# TC80_VXX register map
Vendor: Geneal MCU Ltd.; Series: ARMCM0; File version: 1.2
CPU: CM0 r0p0, little endian, no MPU, no FPU, 2 interrupt priority bits
Registers are 32-bit, read-write, reset 0x0 unless marked. A register's access mark holds for its fields unless they carry their own. Offsets are from the block's base; [hi:lo] are bit positions; {n}, {i} and the like mark numbered series.

## EXTI — External interrupt/event controller
Base 0x4900B000
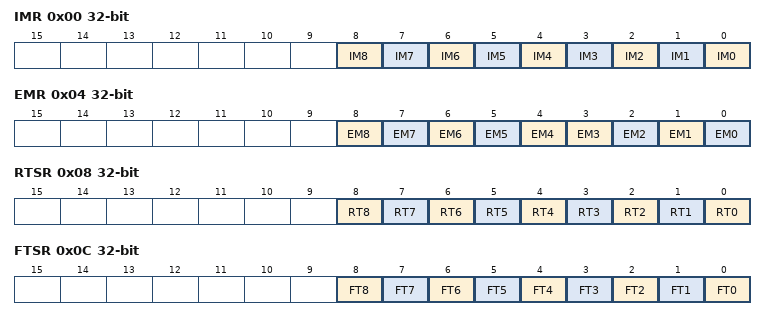
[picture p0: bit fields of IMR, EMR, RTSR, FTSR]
0x00 IMR (reset mask 0x1F) — Interrupt mask register
  [all] fields
    0=Mask (request masked); 1=Un_Mask (request unmasked)
  [n] IM{n} (n=0..8) — Interrupt Mask on line {n}
0x04 EMR — Event mask register
  [8] EM8 — Event Mask on line 8
    0=Mask (request masked); 1=Un_Mask (request unmasked)
  [7] EM7 — Event Mask on line 7
    0=Mask (request masked); 1=Un_Mask (request unmasked)
  [6] EM6 — Event Mask on line 6
  [5] EM5 — Event Mask on line 5
    0=Mask (request masked); 1=Un_Mask (request unmasked)
  [4] EM4 — Event Mask on line 4
  [n] EM{n} (n=0..3) — Event Mask on line {n}
    0=Mask (request masked); 1=Un_Mask (request unmasked)
0x08 RTSR (reset mask 0x1F) — Rising trigger selection register
  [all] fields
    0=Disable (Rising trigger disabled); 1=Enable (Rising trigger enable)
  [n] RT{n} (n=0..8) — Rising trigger event configuration of line {n}
0x0C FTSR (reset mask 0x1F) — Falling trigger selection register
  [all] fields
    0=Disable (Falling trigger disabled); 1=Enable (Falling trigger enable)
  [n] FT{n} (n=0..8) — Falling trigger event configuration of line {n}
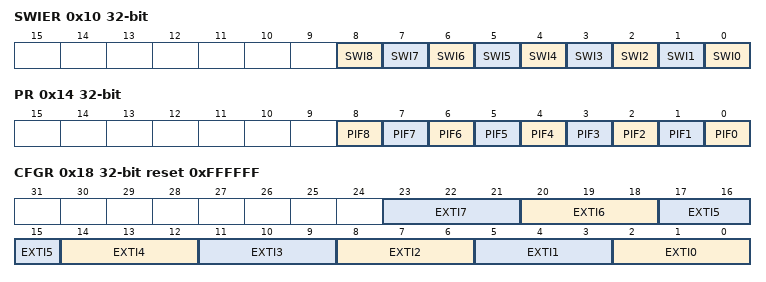
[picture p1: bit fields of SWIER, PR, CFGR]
0x10 SWIER (reset mask 0x1F) — Software interrupt event register
  [n] SWI{n} (n=0..8) — Software Interrupt on line {n}
0x14 PR (reset mask 0x1F) — Pending register
  [n] PIF{n} (n=0..8) — Pending interrupt flag on line {n}
0x18 CFGR reset 0xFFFFFF — line configure register
  [all] fields
    {v}=Select_P{v} (Select port {v}) (v=0..3); 7=Select_None
  [3n+2:3n] EXTI{n} (n=0..7) — Line{n} channel select

## GPIO0 — General-purpose I/Os
Base 0x49001000
Same registers: GPIO1 0x49001400, GPIO2 0x49001800
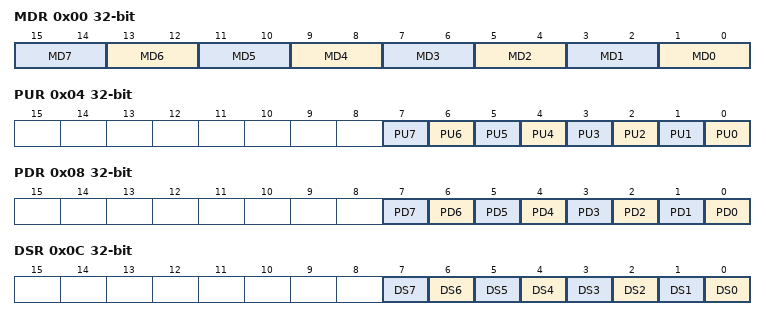
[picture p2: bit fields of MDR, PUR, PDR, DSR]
0x00 MDR — GPIO port mode register
  [all] fields
    0=Input_Mode; 1=Output_Mode (General purpose output mode); 2=Alternate function mode; 3=Analog_Mode
  [2n+1:2n] MD{n} (n=0..7) — Port mode configuration bits
0x04 PUR — GPIO port pull-up register
  [all] fields
    0=Disable (Port pull-up disabled); 1=Enable (Port pull-up enabled)
  [n] PU{n} (n=0..7) — Port pull-up configuration bit
0x08 PDR — GPIO port pull-down register
  [all] fields
    0=Disable (Port pull-down disabled); 1=Enable (Port pull-down enabled)
  [n] PD{n} (n=0..7) — Port pull-down configuration bit
0x0C DSR — GPIO driving strength register
  [all] fields
    0=High (Port driving strength high); 1=Low (Port driving strength low)
  [n] DS{n} (n=0..7) — Port driving strength configuration bit
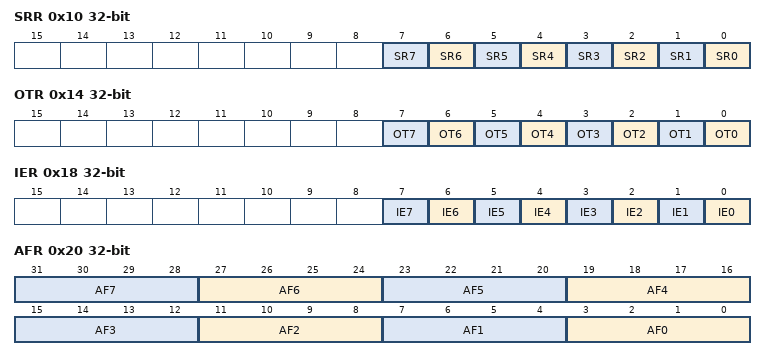
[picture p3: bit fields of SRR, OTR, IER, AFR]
0x10 SRR — GPIO slew rate register
  [all] fields
    0=Fast (Port slew rate fast); 1=Slow (Port slew rate slow)
  [n] SR{n} (n=0..7) — Port slew rate configuration bit
0x14 OTR — GPIO port open type register
  [all] fields
    0=Push pull outputd; 1=Open drain outputd
  [n] OT{n} (n=0..7) — Port open type configuration bit
0x18 IER — GPIO port input enable register
  [all] fields
    0=Disable (Port input enable disabled); 1=Enable (Port input enable enabled)
  [n] IE{n} (n=0..7) — Port input enable configuration bit
0x20 AFR (reset mask 0xFF) — GPIO alternate function register
  [4n+3:4n] AF{n} (n=0..7) — Alternate function select for port
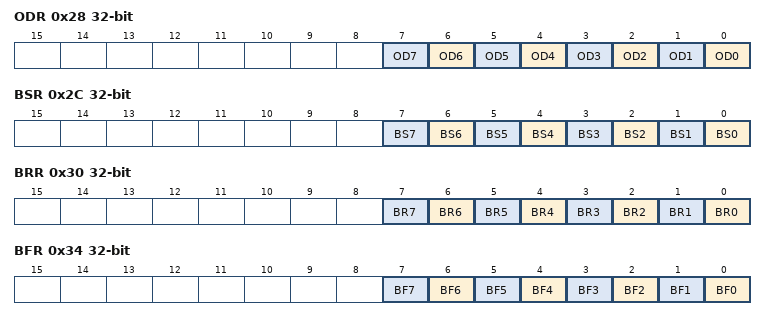
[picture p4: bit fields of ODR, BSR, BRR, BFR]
0x28 ODR — GPIO port output data register
  [n] OD{n} (n=0..7) — Port output data bit
0x2C BSR wo — GPIO port bit set register
  [all] fields
    0=No action on the corresponding OD bit; 1=Set (Set the corresponding OD bit)
  [n] BS{n} (n=0..7) — Port set bit
0x30 BRR wo — GPIO port bit reset register
  [all] fields
    0=No action on the corresponding OD bit; 1=Reset the corresponding OD bit
  [n] BR{n} (n=0..7) — Port reset bit
0x34 BFR wo — GPIO port bit flip register
  [all] fields
    0=No action on the corresponding OD bit; 1=Flip the corresponding OD bit
  [n] BF{n} (n=0..7) — Port flip bit
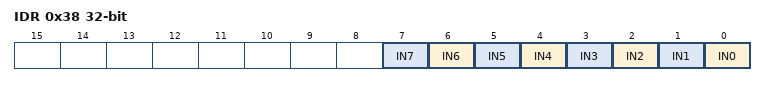
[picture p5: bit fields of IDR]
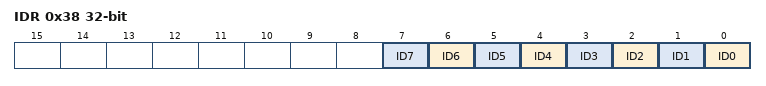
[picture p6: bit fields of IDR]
0x38 IDR ro — GPIO port input data register
  [n] IN{n} (n=0..7) — Port input data bit

## GPIO3 — General-purpose I/Os
Base 0x49001C00
Registers as GPIO0; these are added or differ:
0x38 IDR ro — GPIO port input data register
  [n] ID{n} (n=0..7) — Port input data bit
